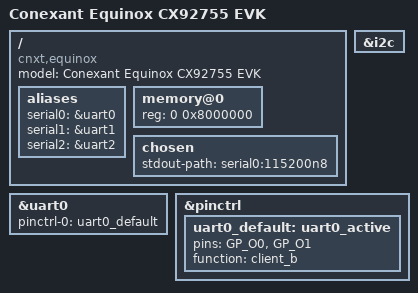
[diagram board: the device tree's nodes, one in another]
/dts-v1/;
#include "cx92755.dtsi"
/ {
	model = "Conexant Equinox CX92755 EVK";
	compatible = "cnxt,equinox", "cnxt,cx92755";
	aliases {
		serial0 = &uart0;
		serial1 = &uart1;
		serial2 = &uart2;
	};
	memory@0 {
		reg = <0 0x8000000>;
		device_type = "memory";
	};
	chosen {
		stdout-path = "serial0:115200n8";
	};
};
&uart0 {
	status = "okay";
	pinctrl-0 = <&uart0_default>;
	pinctrl-names = "default";
};
&i2c {
	status = "okay";
};
&pinctrl {
	uart0_default: uart0_active {
		pins = "GP_O0", "GP_O1";
		function = "client_b";
	};
};
